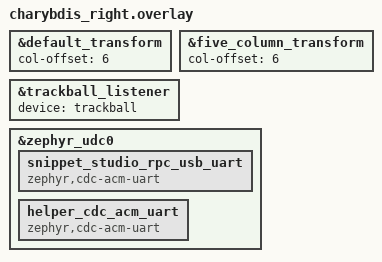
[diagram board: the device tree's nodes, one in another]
/*
 * Copyright (c) 2026 The ZMK Contributors
 * SPDX-License-Identifier: MIT
 *
 * Right Half (Central — режим БЕЗ донгла: подключение к ПК по Bluetooth или USB).
 * Правая половина выступает центральной, локально считывает трекбол PMW3610 и обслуживает ZMK Studio.
 */

#include "charybdis.dtsi"
#include "charybdis_pmw3610.dtsi"

&default_transform {
    col-offset = <6>;
};

&five_column_transform {
    col-offset = <6>;
};

/* На Central слушатель трекбола читает напрямую локальный SPI-сенсор &trackball */
&trackball_listener {
    status = "okay";
    device = <&trackball>;
};

/*
 * Два независимых виртуальных USB CDC-ACM порта при проводном подключении правой половины:
 *   MI_00 (первый) = snippet_studio_rpc_usb_uart -> эксклюзивно для ZMK Studio
 *   MI_02 (второй) = helper_cdc_acm_uart         -> мост управления и телеметрии Charybdis Helper
 */
&zephyr_udc0 {
    snippet_studio_rpc_usb_uart: snippet_studio_rpc_usb_uart {
        compatible = "zephyr,cdc-acm-uart";
    };

    helper_cdc_acm_uart: helper_cdc_acm_uart {
        compatible = "zephyr,cdc-acm-uart";
    };
};

/* Раскомментируйте блок ниже, если на правую половину распаян энкодер EC11: */
/*
&right_encoder {
    status = "okay";
};
*/
